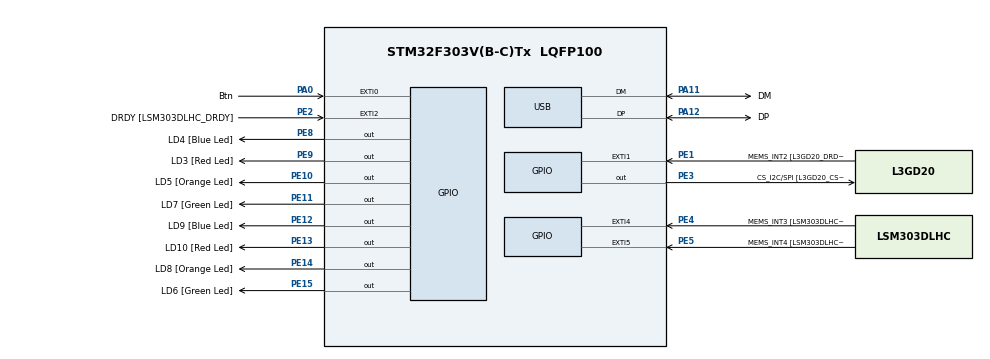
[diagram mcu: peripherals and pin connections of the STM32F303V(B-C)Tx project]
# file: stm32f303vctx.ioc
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Mcu.Family=STM32F3
Mcu.Name=STM32F303V(B-C)Tx
Mcu.Package=LQFP100
NVIC.EXTI0_IRQn=true\:0\:0\:false\:false\:true\:true
NVIC.PriorityGroup=NVIC_PRIORITYGROUP_0
NVIC.USB_LP_CAN_RX0_IRQn=true\:0\:0\:false\:false\:true\:false
PA0.GPIO_Label=Btn
PA0.GPIO_ModeDefaultEXTI=GPIO_MODE_IT_FALLING
PA0.Signal=GPXTI0
PA11.GPIO_Label=DM
PA11.Mode=Device
PA11.Signal=USB_DM
PA12.GPIO_Label=DP
PA12.Mode=Device
PA12.Signal=USB_DP
PA13.GPIO_Label=SWDIO
PA13.Mode=Serial_Wire
PA13.Signal=SYS_JTMS-SWDIO
PA14.GPIO_Label=SWCLK
PA14.Mode=Serial_Wire
PA14.Signal=SYS_JTCK-SWCLK
PA5.GPIO_Label=SPI1_SCK [L3GD20_SCL/SPC]
PA5.Signal=SPI1_SCK
PA6.GPIO_Label=SPI1_MISO [L3GD20_SA0/SDO]
PA6.Signal=SPI1_MISO
PA7.GPIO_Label=SPI1_MISO [L3GD20_SDA/SDI/SDO]
PA7.Signal=SPI1_MOSI
PB3.GPIO_Label=SWO
PB3.Signal=SYS_JTDO-TRACESWO
PB6.GPIO_Label=I2C1_SCL [LSM303DLHC_SCL]
PB6.Signal=I2C1_SCL
PB7.GPIO_Label=I2C1_SDA [LSM303DLHC_SDA]
PB7.Signal=I2C1_SDA
PC14-OSC32_IN.GPIO_Label=OSC32_IN
PC14-OSC32_IN.Signal=RCC_OSC32_IN
PC15-OSC32_OUT.GPIO_Label=OSC32_OUT
PC15-OSC32_OUT.Signal=RCC_OSC32_OUT
PE1.GPIO_Label=MEMS_INT2 [L3GD20_DRDY/INT2]
PE1.GPIO_ModeDefaultEXTI=GPIO_MODE_EVT_RISING
PE1.Signal=GPXTI1
PE10.GPIO_Label=LD5 [Orange Led]
PE10.Signal=GPIO_Output
PE11.GPIO_Label=LD7 [Green Led]
PE11.Signal=GPIO_Output
PE12.GPIO_Label=LD9 [Blue Led]
PE12.Signal=GPIO_Output
PE13.GPIO_Label=LD10 [Red Led]
PE13.Signal=GPIO_Output
PE14.GPIO_Label=LD8 [Orange Led]
PE14.Signal=GPIO_Output
PE15.GPIO_Label=LD6 [Green Led]
PE15.Signal=GPIO_Output
PE2.GPIO_Label=DRDY [LSM303DLHC_DRDY]
PE2.GPIO_ModeDefaultEXTI=GPIO_MODE_EVT_RISING
PE2.Signal=GPXTI2
PE3.GPIO_Label=CS_I2C/SPI [L3GD20_CS_I2C/SPI]
PE3.Signal=GPIO_Output
PE4.GPIO_Label=MEMS_INT3 [LSM303DLHC_INT1]
PE4.GPIO_ModeDefaultEXTI=GPIO_MODE_EVT_RISING
PE4.Signal=GPXTI4
PE5.GPIO_Label=MEMS_INT4 [LSM303DLHC_INT2]
PE5.GPIO_ModeDefaultEXTI=GPIO_MODE_EVT_RISING
PE5.Signal=GPXTI5
PE8.GPIO_Label=LD4 [Blue Led]
PE8.Signal=GPIO_Output
PE9.GPIO_Label=LD3 [Red Led]
PE9.Signal=GPIO_Output
PF0-OSC_IN.GPIO_Label=OSC_IN
PF0-OSC_IN.Mode=HSE-External-Clock-Source
PF0-OSC_IN.Signal=RCC_OSC_IN
PF1-OSC_OUT.GPIO_Label=OSC_OUT
PF1-OSC_OUT.Signal=RCC_OSC_OUT
ProjectManager.HeapSize=0x200
ProjectManager.StackSize=0x400
ProjectManager.TargetToolchain=MDK-ARM V5
RCC.AHBFreq_Value=48000000
RCC.APB1CLKDivider=RCC_HCLK_DIV2
RCC.APB1Freq_Value=24000000
RCC.APB1TimFreq_Value=48000000
RCC.APB2Freq_Value=48000000
RCC.APB2TimFreq_Value=48000000
RCC.CortexFreq_Value=48000000
RCC.HCLKFreq_Value=48000000
RCC.HSE_VALUE=8000000
RCC.HSI_VALUE=8000000
RCC.LSE_VALUE=32768
RCC.PLLMUL=RCC_PLL_MUL6
RCC.SYSCLKFreq_VALUE=48000000
RCC.SYSCLKSourceVirtual=RCC_SYSCLKSOURCE_PLLCLK
RCC.USBFreq_Value=48000000
USB_DEVICE.CLASS_NAME_FS=CUSTOMHID
USB_DEVICE.USBD_CUSTOMHID_OUTREPORT_BUF_SIZE=2
USB_DEVICE.USBD_CUSTOM_HID_REPORT_DESC_SIZE=108
USB_DEVICE.VirtualMode=CustomHid
USB_DEVICE.VirtualModeFS=Custom_Hid_FS
VP_USB_DEVICE_VS_USB_DEVICE_CUSTOM_HID_FS.Mode=CUSTOM_HID_FS
board=STM32F3DISCOVERY

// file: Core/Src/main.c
/* USER CODE BEGIN Header */
/**
  ******************************************************************************
  * @file           : main.c
  * @brief          : Main program body
  ******************************************************************************
  * This notice applies to any and all portions of this file
  * that are not between comment pairs USER CODE BEGIN and
  * USER CODE END. Other portions of this file, whether
  * inserted by the user or by software development tools
  * are owned by their respective copyright owners.
  *
  * Copyright (c) 2019 STMicroelectronics International N.V.
  * All rights reserved.
  *
  * Redistribution and use in source and binary forms, with or without
  * modification, are permitted, provided that the following conditions are met:
  *
  * 1. Redistribution of source code must retain the above copyright notice,
  *    this list of conditions and the following disclaimer.
  * 2. Redistributions in binary form must reproduce the above copyright notice,
  *    this list of conditions and the following disclaimer in the documentation
  *    and/or other materials provided with the distribution.
  * 3. Neither the name of STMicroelectronics nor the names of other
  *    contributors to this software may be used to endorse or promote products
  *    derived from this software without specific written permission.
  * 4. This software, including modifications and/or derivative works of this
  *    software, must execute solely and exclusively on microcontroller or
  *    microprocessor devices manufactured by or for STMicroelectronics.
  * 5. Redistribution and use of this software other than as permitted under
  *    this license is void and will automatically terminate your rights under
  *    this license.
  *
  * THIS SOFTWARE IS PROVIDED BY STMICROELECTRONICS AND CONTRIBUTORS "AS IS"
  * AND ANY EXPRESS, IMPLIED OR STATUTORY WARRANTIES, INCLUDING, BUT NOT
  * LIMITED TO, THE IMPLIED WARRANTIES OF MERCHANTABILITY, FITNESS FOR A
  * PARTICULAR PURPOSE AND NON-INFRINGEMENT OF THIRD PARTY INTELLECTUAL PROPERTY
  * RIGHTS ARE DISCLAIMED TO THE FULLEST EXTENT PERMITTED BY LAW. IN NO EVENT
  * SHALL STMICROELECTRONICS OR CONTRIBUTORS BE LIABLE FOR ANY DIRECT, INDIRECT,
  * INCIDENTAL, SPECIAL, EXEMPLARY, OR CONSEQUENTIAL DAMAGES (INCLUDING, BUT NOT
  * LIMITED TO, PROCUREMENT OF SUBSTITUTE GOODS OR SERVICES; LOSS OF USE, DATA,
  * OR PROFITS; OR BUSINESS INTERRUPTION) HOWEVER CAUSED AND ON ANY THEORY OF
  * LIABILITY, WHETHER IN CONTRACT, STRICT LIABILITY, OR TORT (INCLUDING
  * NEGLIGENCE OR OTHERWISE) ARISING IN ANY WAY OUT OF THE USE OF THIS SOFTWARE,
  * EVEN IF ADVISED OF THE POSSIBILITY OF SUCH DAMAGE.
  *
  ******************************************************************************
  */
/* USER CODE END Header */

#include "main.h"
#include "usb_device.h"

/* USER CODE BEGIN Includes */
//#include "usbd_customhid.h"
/* USER CODE END Includes */

void SystemClock_Config(void);
static void MX_GPIO_Init(void);

int main(void)
{

  /* MCU Configuration--------------------------------------------------------*/

  /* Reset of all peripherals, Initializes the Flash interface and the Systick. */
  HAL_Init();

  /* Configure the system clock */
  SystemClock_Config();

  /* Initialize all configured peripherals */
  MX_GPIO_Init();
  MX_USB_DEVICE_Init();

  /* Infinite loop */
  while (1)
  {

  }
}

void SystemClock_Config(void)
{
  LL_FLASH_SetLatency(LL_FLASH_LATENCY_1);

  if(LL_FLASH_GetLatency() != LL_FLASH_LATENCY_1)
  {
  Error_Handler();
  }
  LL_RCC_HSE_EnableBypass();
  LL_RCC_HSE_Enable();

   /* Wait till HSE is ready */
  while(LL_RCC_HSE_IsReady() != 1)
  {

  }
  LL_RCC_PLL_ConfigDomain_SYS(LL_RCC_PLLSOURCE_HSE_DIV_1, LL_RCC_PLL_MUL_6);
  LL_RCC_PLL_Enable();

   /* Wait till PLL is ready */
  while(LL_RCC_PLL_IsReady() != 1)
  {

  }
  LL_RCC_SetAHBPrescaler(LL_RCC_SYSCLK_DIV_1);
  LL_RCC_SetAPB1Prescaler(LL_RCC_APB1_DIV_2);
  LL_RCC_SetAPB2Prescaler(LL_RCC_APB1_DIV_1);
  LL_RCC_SetSysClkSource(LL_RCC_SYS_CLKSOURCE_PLL);

   /* Wait till System clock is ready */
  while(LL_RCC_GetSysClkSource() != LL_RCC_SYS_CLKSOURCE_STATUS_PLL)
  {

  }
  LL_Init1msTick(48000000);
  LL_SYSTICK_SetClkSource(LL_SYSTICK_CLKSOURCE_HCLK);
  LL_SetSystemCoreClock(48000000);
  LL_RCC_SetUSBClockSource(LL_RCC_USB_CLKSOURCE_PLL);
}

static void MX_GPIO_Init(void)
{
  LL_GPIO_InitTypeDef GPIO_InitStruct = {0};
  LL_EXTI_InitTypeDef EXTI_InitStruct = {0};

  /* GPIO Ports Clock Enable */
  LL_AHB1_GRP1_EnableClock(LL_AHB1_GRP1_PERIPH_GPIOE);
  LL_AHB1_GRP1_EnableClock(LL_AHB1_GRP1_PERIPH_GPIOC);
  LL_AHB1_GRP1_EnableClock(LL_AHB1_GRP1_PERIPH_GPIOF);
  LL_AHB1_GRP1_EnableClock(LL_AHB1_GRP1_PERIPH_GPIOA);
  LL_AHB1_GRP1_EnableClock(LL_AHB1_GRP1_PERIPH_GPIOB);

  /**/
  LL_GPIO_ResetOutputPin(GPIOE, CS_I2C_SPI_Pin|LD4_Pin|LD3_Pin|LD5_Pin
                          |LD7_Pin|LD9_Pin|LD10_Pin|LD8_Pin
                          |LD6_Pin);

  /**/
  LL_SYSCFG_SetEXTISource(LL_SYSCFG_EXTI_PORTE, LL_SYSCFG_EXTI_LINE2);

  /**/
  LL_SYSCFG_SetEXTISource(LL_SYSCFG_EXTI_PORTE, LL_SYSCFG_EXTI_LINE4);

  /**/
  LL_SYSCFG_SetEXTISource(LL_SYSCFG_EXTI_PORTE, LL_SYSCFG_EXTI_LINE5);

  /**/
  LL_SYSCFG_SetEXTISource(LL_SYSCFG_EXTI_PORTA, LL_SYSCFG_EXTI_LINE0);

  /**/
  LL_SYSCFG_SetEXTISource(LL_SYSCFG_EXTI_PORTE, LL_SYSCFG_EXTI_LINE1);

  /**/
  LL_GPIO_SetPinPull(DRDY_GPIO_Port, DRDY_Pin, LL_GPIO_PULL_NO);

  /**/
  LL_GPIO_SetPinPull(MEMS_INT3_GPIO_Port, MEMS_INT3_Pin, LL_GPIO_PULL_NO);

  /**/
  LL_GPIO_SetPinPull(MEMS_INT4_GPIO_Port, MEMS_INT4_Pin, LL_GPIO_PULL_NO);

  /**/
  LL_GPIO_SetPinPull(Btn_GPIO_Port, Btn_Pin, LL_GPIO_PULL_NO);

  /**/
  LL_GPIO_SetPinPull(MEMS_INT2_GPIO_Port, MEMS_INT2_Pin, LL_GPIO_PULL_NO);

  /**/
  LL_GPIO_SetPinMode(DRDY_GPIO_Port, DRDY_Pin, LL_GPIO_MODE_INPUT);

  /**/
  LL_GPIO_SetPinMode(MEMS_INT3_GPIO_Port, MEMS_INT3_Pin, LL_GPIO_MODE_INPUT);

  /**/
  LL_GPIO_SetPinMode(MEMS_INT4_GPIO_Port, MEMS_INT4_Pin, LL_GPIO_MODE_INPUT);

  /**/
  LL_GPIO_SetPinMode(Btn_GPIO_Port, Btn_Pin, LL_GPIO_MODE_INPUT);

  /**/
  LL_GPIO_SetPinMode(MEMS_INT2_GPIO_Port, MEMS_INT2_Pin, LL_GPIO_MODE_INPUT);

  /**/
  EXTI_InitStruct.Line_0_31 = LL_EXTI_LINE_2;
  EXTI_InitStruct.Line_32_63 = LL_EXTI_LINE_NONE;
  EXTI_InitStruct.LineCommand = ENABLE;
  EXTI_InitStruct.Mode = LL_EXTI_MODE_EVENT;
  EXTI_InitStruct.Trigger = LL_EXTI_TRIGGER_RISING;
  LL_EXTI_Init(&EXTI_InitStruct);

  /**/
  EXTI_InitStruct.Line_0_31 = LL_EXTI_LINE_4;
  EXTI_InitStruct.Line_32_63 = LL_EXTI_LINE_NONE;
  EXTI_InitStruct.LineCommand = ENABLE;
  EXTI_InitStruct.Mode = LL_EXTI_MODE_EVENT;
  EXTI_InitStruct.Trigger = LL_EXTI_TRIGGER_RISING;
  LL_EXTI_Init(&EXTI_InitStruct);

  /**/
  EXTI_InitStruct.Line_0_31 = LL_EXTI_LINE_5;
  EXTI_InitStruct.Line_32_63 = LL_EXTI_LINE_NONE;
  EXTI_InitStruct.LineCommand = ENABLE;
  EXTI_InitStruct.Mode = LL_EXTI_MODE_EVENT;
  EXTI_InitStruct.Trigger = LL_EXTI_TRIGGER_RISING;
  LL_EXTI_Init(&EXTI_InitStruct);

  /**/
  EXTI_InitStruct.Line_0_31 = LL_EXTI_LINE_0;
  EXTI_InitStruct.Line_32_63 = LL_EXTI_LINE_NONE;
  EXTI_InitStruct.LineCommand = ENABLE;
  EXTI_InitStruct.Mode = LL_EXTI_MODE_IT;
  EXTI_InitStruct.Trigger = LL_EXTI_TRIGGER_FALLING;
  LL_EXTI_Init(&EXTI_InitStruct);

  /**/
  EXTI_InitStruct.Line_0_31 = LL_EXTI_LINE_1;
  EXTI_InitStruct.Line_32_63 = LL_EXTI_LINE_NONE;
  EXTI_InitStruct.LineCommand = ENABLE;
  EXTI_InitStruct.Mode = LL_EXTI_MODE_EVENT;
  EXTI_InitStruct.Trigger = LL_EXTI_TRIGGER_RISING;
  LL_EXTI_Init(&EXTI_InitStruct);

  /**/
  GPIO_InitStruct.Pin = CS_I2C_SPI_Pin|LD4_Pin|LD3_Pin|LD5_Pin
                          |LD7_Pin|LD9_Pin|LD10_Pin|LD8_Pin
                          |LD6_Pin;
  GPIO_InitStruct.Mode = LL_GPIO_MODE_OUTPUT;
  GPIO_InitStruct.Speed = LL_GPIO_SPEED_FREQ_LOW;
  GPIO_InitStruct.OutputType = LL_GPIO_OUTPUT_PUSHPULL;
  GPIO_InitStruct.Pull = LL_GPIO_PULL_NO;
  LL_GPIO_Init(GPIOE, &GPIO_InitStruct);

  /**/
  GPIO_InitStruct.Pin = SPI1_SCK_Pin|SPI1_MISO_Pin|SPI1_MISOA7_Pin;
  GPIO_InitStruct.Mode = LL_GPIO_MODE_ALTERNATE;
  GPIO_InitStruct.Speed = LL_GPIO_SPEED_FREQ_HIGH;
  GPIO_InitStruct.OutputType = LL_GPIO_OUTPUT_PUSHPULL;
  GPIO_InitStruct.Pull = LL_GPIO_PULL_NO;
  GPIO_InitStruct.Alternate = LL_GPIO_AF_5;
  LL_GPIO_Init(GPIOA, &GPIO_InitStruct);

  /**/
  GPIO_InitStruct.Pin = I2C1_SCL_Pin|I2C1_SDA_Pin;
  GPIO_InitStruct.Mode = LL_GPIO_MODE_ALTERNATE;
  GPIO_InitStruct.Speed = LL_GPIO_SPEED_FREQ_HIGH;
  GPIO_InitStruct.OutputType = LL_GPIO_OUTPUT_OPENDRAIN;
  GPIO_InitStruct.Pull = LL_GPIO_PULL_UP;
  GPIO_InitStruct.Alternate = LL_GPIO_AF_4;
  LL_GPIO_Init(GPIOB, &GPIO_InitStruct);

  /* EXTI interrupt init*/
  NVIC_SetPriority(EXTI0_IRQn, NVIC_EncodePriority(NVIC_GetPriorityGrouping(),0, 0));
  NVIC_EnableIRQ(EXTI0_IRQn);

}

void Error_Handler(void)
{
}

/************************ (C) COPYRIGHT STMicroelectronics *****END OF FILE****/
